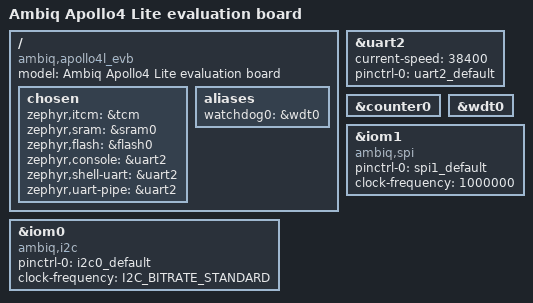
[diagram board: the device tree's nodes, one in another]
/dts-v1/;
#include <ambiq/ambiq_apollo4l.dtsi>

#include "apollo4l_evb-pinctrl.dtsi"

/ {
	model = "Ambiq Apollo4 Lite evaluation board";
	compatible = "ambiq,apollo4l_evb";
	chosen {
		zephyr,itcm = &tcm;
		zephyr,sram = &sram0;
		zephyr,flash = &flash0;
		zephyr,console = &uart2;
		zephyr,shell-uart = &uart2;
		zephyr,uart-pipe = &uart2;
	};
	aliases {
		watchdog0 = &wdt0;
	};
};

&uart2 {
	current-speed = <38400>;
	pinctrl-0 = <&uart2_default>;
	pinctrl-names = "default";
	status = "okay";
};

&counter0 {
	status = "okay";
};

&wdt0 {
	status = "okay";
};

&iom0 {
	compatible = "ambiq,i2c";
	pinctrl-0 = <&i2c0_default>;
	pinctrl-names = "default";
	clock-frequency = <I2C_BITRATE_STANDARD>;
	status = "okay";
};

&iom1 {
	compatible = "ambiq,spi";
	pinctrl-0 = <&spi1_default>;
	pinctrl-names = "default";
	clock-frequency = <1000000>;
	status = "okay";
};
